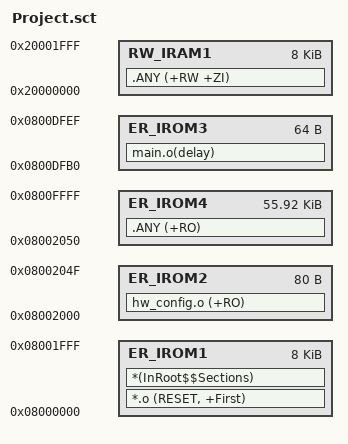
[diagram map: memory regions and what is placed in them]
; *************************************************************
; *** Scatter-Loading Description File generated by uVision ***
; *************************************************************

LR_IROM1 0x08000000 0x00002000  {    ; load region size_region
  ER_IROM1 0x08000000 0x00002000  {  ; load address = execution address
   *.o (RESET, +First)
   *(InRoot$$Sections)
  }

  RW_IRAM1 0x20000000 0x00002000  {  ; RW data
   .ANY (+RW +ZI)
  }
}

 LR_IROM2 0x08002000 0x0000050  {
   ER_IROM2 0x08002000 0x0000050  {  ; 将hw_config.c文件分散加载到0x08002000以后的区域
   hw_config.o (+RO)
  }
 }
 
 LR_IROM3 0x0800dfb0 0x0000040  {
   ER_IROM3 0x0800dfb0 0x0000040  {  ; 将main.c中delay()函数定义为section“delay”，然后分散加载到0x0800dfb0以后的区域
   main.o(delay)
  }
 }
 
 LR_IROM4 0x08002050 0x000dfb0  {
   ER_IROM4 0x08002050 0x000dfb0  {  ; load address = execution address
   .ANY (+RO)
  }
 }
